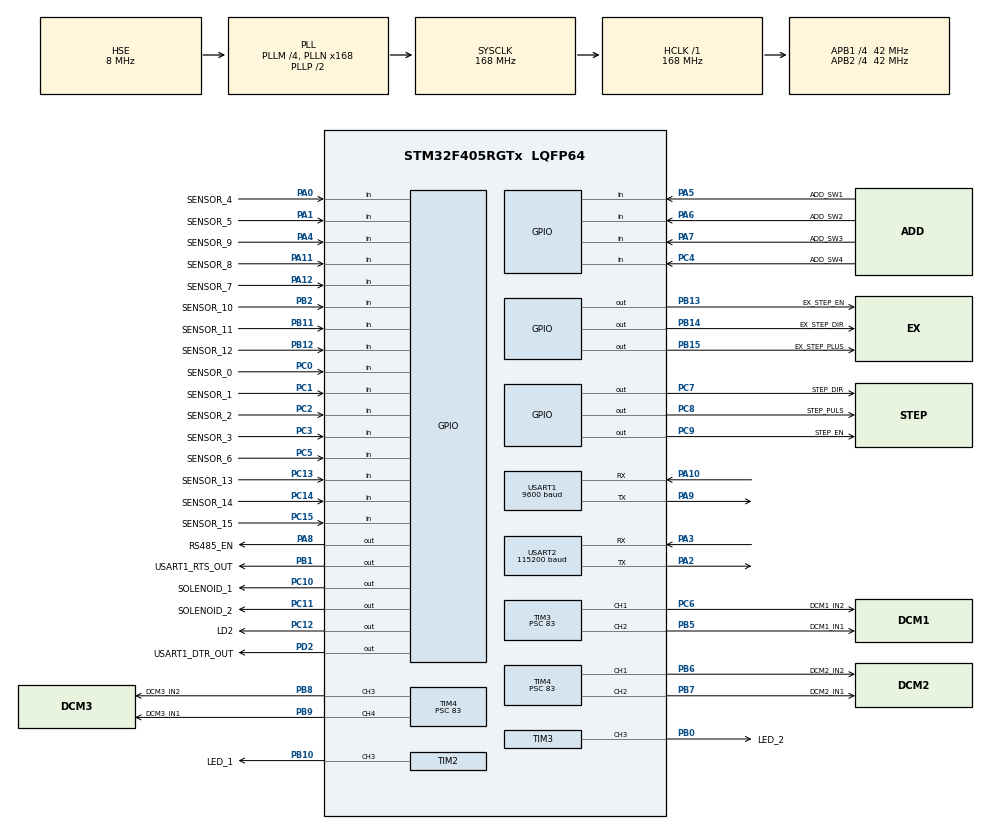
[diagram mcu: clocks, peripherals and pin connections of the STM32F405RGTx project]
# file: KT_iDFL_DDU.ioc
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Mcu.Family=STM32F4
Mcu.Name=STM32F405RGTx
Mcu.Package=LQFP64
NVIC.PriorityGroup=NVIC_PRIORITYGROUP_4
NVIC.TIM1_TRG_COM_TIM11_IRQn=true\:0\:0\:false\:false\:true\:true\:true
NVIC.TIM1_UP_TIM10_IRQn=true\:0\:0\:false\:false\:true\:true\:true
NVIC.TIM6_DAC_IRQn=true\:0\:0\:false\:false\:true\:true\:true
NVIC.TIM7_IRQn=true\:0\:0\:false\:false\:true\:true\:true
NVIC.USART1_IRQn=true\:0\:0\:false\:false\:true\:true\:true
NVIC.USART2_IRQn=true\:0\:0\:false\:false\:true\:true\:true
PA0-WKUP.GPIO_Label=SENSOR_4
PA0-WKUP.GPIO_PuPd=GPIO_PULLUP
PA0-WKUP.Signal=GPIO_Input
PA1.GPIO_Label=SENSOR_5
PA1.GPIO_PuPd=GPIO_PULLUP
PA1.Signal=GPIO_Input
PA10.GPIO_ModeDefaultPP=GPIO_MODE_AF_PP
PA10.GPIO_PuPd=GPIO_NOPULL
PA10.GPIO_Speed=GPIO_SPEED_FREQ_VERY_HIGH
PA10.Mode=Asynchronous
PA10.Signal=USART1_RX
PA11.GPIO_Label=SENSOR_8
PA11.GPIO_PuPd=GPIO_PULLUP
PA11.Signal=GPIO_Input
PA12.GPIO_Label=SENSOR_7
PA12.GPIO_PuPd=GPIO_PULLUP
PA12.Signal=GPIO_Input
PA13.Mode=JTAG_5_pins
PA13.Signal=SYS_JTMS-SWDIO
PA14.Mode=JTAG_5_pins
PA14.Signal=SYS_JTCK-SWCLK
PA15.Mode=JTAG_5_pins
PA15.Signal=SYS_JTDI
PA2.Mode=Asynchronous
PA2.Signal=USART2_TX
PA3.Mode=Asynchronous
PA3.Signal=USART2_RX
PA4.GPIO_Label=SENSOR_9
PA4.GPIO_PuPd=GPIO_PULLUP
PA4.Signal=GPIO_Input
PA5.GPIO_Label=ADD_SW1
PA5.GPIO_PuPd=GPIO_PULLUP
PA5.Signal=GPIO_Input
PA6.GPIO_Label=ADD_SW2
PA6.GPIO_PuPd=GPIO_PULLUP
PA6.Signal=GPIO_Input
PA7.GPIO_Label=ADD_SW3
PA7.GPIO_PuPd=GPIO_PULLUP
PA7.Signal=GPIO_Input
PA8.GPIO_Label=RS485_EN
PA8.Signal=GPIO_Output
PA9.Mode=Asynchronous
PA9.Signal=USART1_TX
PB0.GPIO_Label=LED_2
PB0.Signal=S_TIM3_CH3
PB1.GPIO_Label=USART1_RTS_OUT
PB1.Signal=GPIO_Output
PB10.GPIO_Label=LED_1
PB10.Signal=S_TIM2_CH3
PB11.GPIO_Label=SENSOR_11
PB11.GPIO_PuPd=GPIO_PULLUP
PB11.Signal=GPIO_Input
PB12.GPIO_Label=SENSOR_12
PB12.GPIO_PuPd=GPIO_PULLUP
PB12.Signal=GPIO_Input
PB13.GPIO_Label=EX_STEP_EN
PB13.Signal=GPIO_Output
PB14.GPIO_Label=EX_STEP_DIR
PB14.Signal=GPIO_Output
PB15.GPIO_Label=EX_STEP_PLUS
PB15.Signal=GPIO_Output
PB2.GPIO_Label=SENSOR_10
PB2.GPIO_PuPd=GPIO_PULLDOWN
PB2.Signal=GPIO_Input
PB3.Mode=JTAG_5_pins
PB3.Signal=SYS_JTDO-SWO
PB4.Mode=JTAG_5_pins
PB4.Signal=SYS_JTRST
PB5.GPIO_Label=DCM1_IN1
PB5.Signal=S_TIM3_CH2
PB6.GPIO_Label=DCM2_IN2
PB6.Signal=S_TIM4_CH1
PB7.GPIO_Label=DCM2_IN1
PB7.Signal=S_TIM4_CH2
PB8.GPIO_Label=DCM3_IN2
PB8.Signal=S_TIM4_CH3
PB9.GPIO_Label=DCM3_IN1
PB9.Signal=S_TIM4_CH4
PC0.GPIO_Label=SENSOR_0
PC0.GPIO_PuPd=GPIO_PULLUP
PC0.Signal=GPIO_Input
PC1.GPIO_Label=SENSOR_1
PC1.GPIO_PuPd=GPIO_PULLUP
PC1.Signal=GPIO_Input
PC10.GPIO_Label=SOLENOID_1
PC10.Signal=GPIO_Output
PC11.GPIO_Label=SOLENOID_2
PC11.Signal=GPIO_Output
PC12.GPIO_Label=LD2
PC12.Signal=GPIO_Output
PC13-ANTI_TAMP.GPIO_Label=SENSOR_13
PC13-ANTI_TAMP.GPIO_PuPd=GPIO_PULLUP
PC13-ANTI_TAMP.Signal=GPIO_Input
PC14-OSC32_IN.GPIO_Label=SENSOR_14
PC14-OSC32_IN.GPIO_PuPd=GPIO_PULLUP
PC14-OSC32_IN.Signal=GPIO_Input
PC15-OSC32_OUT.GPIO_Label=SENSOR_15
PC15-OSC32_OUT.GPIO_PuPd=GPIO_PULLUP
PC15-OSC32_OUT.Signal=GPIO_Input
PC2.GPIO_Label=SENSOR_2
PC2.GPIO_PuPd=GPIO_PULLUP
PC2.Signal=GPIO_Input
PC3.GPIO_Label=SENSOR_3
PC3.GPIO_PuPd=GPIO_PULLUP
PC3.Signal=GPIO_Input
PC4.GPIO_Label=ADD_SW4
PC4.GPIO_PuPd=GPIO_PULLUP
PC4.Signal=GPIO_Input
PC5.GPIO_Label=SENSOR_6
PC5.GPIO_PuPd=GPIO_PULLUP
PC5.Signal=GPIO_Input
PC6.GPIO_Label=DCM1_IN2
PC6.Signal=S_TIM3_CH1
PC7.GPIO_Label=STEP_DIR
PC7.Signal=GPIO_Output
PC8.GPIO_Label=STEP_PULS
PC8.Signal=GPIO_Output
PC9.GPIO_Label=STEP_EN
PC9.Signal=GPIO_Output
PD2.GPIO_Label=USART1_DTR_OUT
PD2.Signal=GPIO_Output
PH0-OSC_IN.Mode=HSE-External-Oscillator
PH0-OSC_IN.Signal=RCC_OSC_IN
PH1-OSC_OUT.Mode=HSE-External-Oscillator
PH1-OSC_OUT.Signal=RCC_OSC_OUT
ProjectManager.HeapSize=0x200
ProjectManager.StackSize=0x400
ProjectManager.TargetToolchain=MDK-ARM V5
RCC.48MHZClocksFreq_Value=84000000
RCC.AHBFreq_Value=168000000
RCC.APB1CLKDivider=RCC_HCLK_DIV4
RCC.APB1Freq_Value=42000000
RCC.APB1TimFreq_Value=84000000
RCC.APB2CLKDivider=RCC_HCLK_DIV4
RCC.APB2Freq_Value=42000000
RCC.APB2TimFreq_Value=84000000
RCC.CortexFreq_Value=168000000
RCC.HCLKFreq_Value=168000000
RCC.HSE_VALUE=8000000
RCC.HSI_VALUE=16000000
RCC.LSE_VALUE=32768
RCC.PLLM=4
RCC.PLLN=168
RCC.PLLSourceVirtual=RCC_PLLSOURCE_HSE
RCC.SYSCLKFreq_VALUE=168000000
RCC.SYSCLKSource=RCC_SYSCLKSOURCE_PLLCLK
RCC.VCOOutputFreq_Value=336000000
SH.S_TIM2_CH3.0=TIM2_CH3,PWM Generation3 CH3
SH.S_TIM3_CH1.0=TIM3_CH1,PWM Generation1 CH1
SH.S_TIM3_CH2.0=TIM3_CH2,PWM Generation2 CH2
SH.S_TIM3_CH3.0=TIM3_CH3,PWM Generation3 CH3
SH.S_TIM4_CH1.0=TIM4_CH1,PWM Generation1 CH1
SH.S_TIM4_CH2.0=TIM4_CH2,PWM Generation2 CH2
SH.S_TIM4_CH3.0=TIM4_CH3,PWM Generation3 CH3
SH.S_TIM4_CH4.0=TIM4_CH4,PWM Generation4 CH4
TIM10.AutoReloadPreload=TIM_AUTORELOAD_PRELOAD_ENABLE
TIM10.Period=9
TIM10.Prescaler=41
TIM11.Period=3
TIM11.Prescaler=83
TIM2.Channel-PWM\ Generation3\ CH3=TIM_CHANNEL_3
TIM2.OC3Preload_PWM=DISABLE
TIM2.Period=999
TIM2.Prescaler=83
TIM3.Channel-PWM\ Generation1\ CH1=TIM_CHANNEL_1
TIM3.Channel-PWM\ Generation2\ CH2=TIM_CHANNEL_2
TIM3.Channel-PWM\ Generation3\ CH3=TIM_CHANNEL_3
TIM3.OC1Preload_PWM=DISABLE
TIM3.OC2Preload_PWM=DISABLE
TIM3.OC3Preload_PWM=DISABLE
TIM3.Period=999
TIM3.Prescaler=83
TIM4.Channel-PWM\ Generation1\ CH1=TIM_CHANNEL_1
TIM4.Channel-PWM\ Generation2\ CH2=TIM_CHANNEL_2
TIM4.Channel-PWM\ Generation3\ CH3=TIM_CHANNEL_3
TIM4.Channel-PWM\ Generation4\ CH4=TIM_CHANNEL_4
TIM4.Period=999
TIM4.Prescaler=83
TIM6.AutoReloadPreload=TIM_AUTORELOAD_PRELOAD_ENABLE
TIM6.Period=9
TIM6.Prescaler=41
TIM7.Period=3
TIM7.Prescaler=83
USART1.BaudRate=9600
USART1.VirtualMode=VM_ASYNC
USART2.BaudRate=115200
USART2.VirtualMode=VM_ASYNC
VP_TIM10_VS_ClockSourceINT.Mode=Enable_Timer
VP_TIM11_VS_ClockSourceINT.Mode=Enable_Timer
VP_TIM6_VS_ClockSourceINT.Mode=Enable_Timer
VP_TIM7_VS_ClockSourceINT.Mode=Enable_Timer
board=custom

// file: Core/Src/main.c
/* USER CODE BEGIN Header */
/**
  ******************************************************************************
  * @file           : main.c
  * @brief          : Main program body
  ******************************************************************************
  * @attention
  *
  * <h2><center>&copy; Copyright (c) 2021 STMicroelectronics.
  * All rights reserved.</center></h2>
  *
  * This software component is licensed by ST under BSD 3-Clause license,
  * the "License"; You may not use this file except in compliance with the
  * License. You may obtain a copy of the License at:
  *                        opensource.org/licenses/BSD-3-Clause
  *
  ******************************************************************************
  */
/* USER CODE END Header */
#include "main.h"
#include "tim.h"
#include "usart.h"//hhhhhhhhhhhhhhhhhhhhhhhhhhhhhhhhhhhhhhh
#include "gpio.h"

/* USER CODE BEGIN Includes */
#include "IDFL_Proc.hpp"
/* USER CODE END Includes */

void SystemClock_Config(void);

int main(void)
{

  /* MCU Configuration--------------------------------------------------------*/

  /* Reset of all peripherals, Initializes the Flash interface and the Systick. */
  HAL_Init();

  /* Configure the system clock */
  SystemClock_Config();

  /* Initialize all configured peripherals */
  MX_GPIO_Init();
  MX_USART1_UART_Init();
  MX_USART2_UART_Init();
  MX_TIM6_Init();
  MX_TIM7_Init();
  MX_TIM2_Init();
  MX_TIM3_Init();
  MX_TIM4_Init();
  MX_TIM10_Init();
  MX_TIM11_Init();
  /* USER CODE BEGIN 2 */
	setup();
  /* USER CODE END 2 */

  /* Infinite loop */
  /* USER CODE BEGIN WHILE */
  while (1)
  {
		loop();
    /* USER CODE END WHILE */

  }
}

void SystemClock_Config(void)
{
  RCC_OscInitTypeDef RCC_OscInitStruct = {0};
  RCC_ClkInitTypeDef RCC_ClkInitStruct = {0};

  /** Configure the main internal regulator output voltage
  */
  __HAL_RCC_PWR_CLK_ENABLE();
  __HAL_PWR_VOLTAGESCALING_CONFIG(PWR_REGULATOR_VOLTAGE_SCALE1);
  /** Initializes the RCC Oscillators according to the specified parameters
  * in the RCC_OscInitTypeDef structure.
  */
  RCC_OscInitStruct.OscillatorType = RCC_OSCILLATORTYPE_HSE;
  RCC_OscInitStruct.HSEState = RCC_HSE_ON;
  RCC_OscInitStruct.PLL.PLLState = RCC_PLL_ON;
  RCC_OscInitStruct.PLL.PLLSource = RCC_PLLSOURCE_HSE;
  RCC_OscInitStruct.PLL.PLLM = 4;
  RCC_OscInitStruct.PLL.PLLN = 168;
  RCC_OscInitStruct.PLL.PLLP = RCC_PLLP_DIV2;
  RCC_OscInitStruct.PLL.PLLQ = 4;
  if (HAL_RCC_OscConfig(&RCC_OscInitStruct) != HAL_OK)
  {
    Error_Handler();
  }
  /** Initializes the CPU, AHB and APB buses clocks
  */
  RCC_ClkInitStruct.ClockType = RCC_CLOCKTYPE_HCLK|RCC_CLOCKTYPE_SYSCLK
                              |RCC_CLOCKTYPE_PCLK1|RCC_CLOCKTYPE_PCLK2;
  RCC_ClkInitStruct.SYSCLKSource = RCC_SYSCLKSOURCE_PLLCLK;
  RCC_ClkInitStruct.AHBCLKDivider = RCC_SYSCLK_DIV1;
  RCC_ClkInitStruct.APB1CLKDivider = RCC_HCLK_DIV4;
  RCC_ClkInitStruct.APB2CLKDivider = RCC_HCLK_DIV4;

  if (HAL_RCC_ClockConfig(&RCC_ClkInitStruct, FLASH_LATENCY_5) != HAL_OK)
  {
    Error_Handler();
  }
}

void Error_Handler(void)
{
  __disable_irq();
  while (1)
  {
  }
}

/************************ (C) COPYRIGHT STMicroelectronics *****END OF FILE****/
